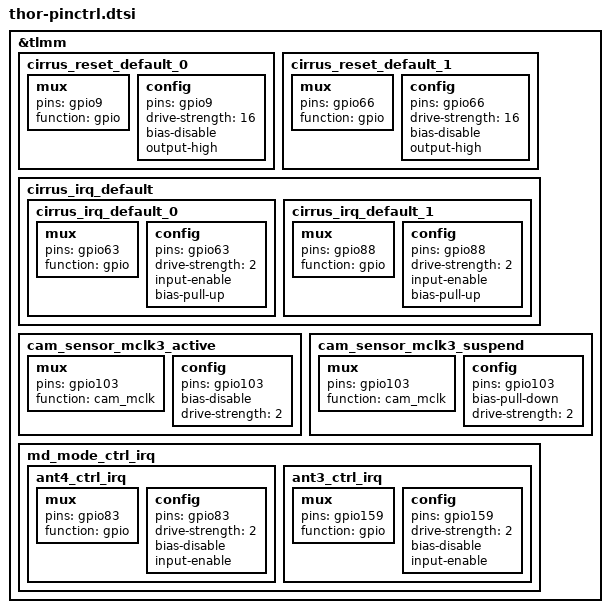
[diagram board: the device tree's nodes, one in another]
/*for thor pinctrl */

&tlmm {
	cirrus_reset_default_0: cirrus_reset_default_0 {
		mux {
			pins = "gpio9";
			function = "gpio";
		};

		config {
			pins = "gpio9";
			drive-strength = <16>;   /* 16 mA */
			bias-disable;
			output-high;
		};
	};

	cirrus_reset_default_1: cirrus_reset_default_1 {
		mux {
			pins = "gpio66";
			function = "gpio";
		};

		config {
			pins = "gpio66";
			drive-strength = <16>;   /* 16 mA */
			bias-disable;
			output-high;
		};
	};

	cirrus_irq_default {
		cirrus_irq_default_0: cirrus_irq_default_0 {
			mux {
					pins = "gpio63";
					function = "gpio";
			};
			config {
					pins = "gpio63";
					drive-strength = <2>;
					input-enable;
					bias-pull-up;
			};
		};
		cirrus_irq_default_1: cirrus_irq_default_1 {
			mux {
					pins = "gpio88";
					function = "gpio";
			};
			config {
					pins = "gpio88";
					drive-strength = <2>;
					input-enable;
					bias-pull-up;
			};
		};
	};

	cam_sensor_mclk3_active: cam_sensor_mclk3_active {
		/* MCLK3 */
		mux {
			pins = "gpio103";
			function = "cam_mclk";
		};

		config {
			pins = "gpio103";
			bias-disable; /* No PULL */
			drive-strength = <2>; /* 2 MA */
		};
	};

	cam_sensor_mclk3_suspend: cam_sensor_mclk3_suspend {
		/* MCLK3 */
		mux {
			pins = "gpio103";
			function = "cam_mclk";
		};

		config {
			pins = "gpio103";
			bias-pull-down; /* PULL DOWN */
			drive-strength = <2>; /* 2 MA */
		};
	};

	md_mode_ctrl_irq {
		ant4_ctrl_irq: ant4_ctrl_irq {
			mux {
				pins = "gpio83";
				function = "gpio";
			};

			config {
				pins = "gpio83";
				drive-strength = <2>;
				bias-disable;
				input-enable;
			};
		};

		ant3_ctrl_irq: ant3_ctrl_irq {
			mux {
				pins = "gpio159";
				function = "gpio";
			};

			config {
				pins = "gpio159";
				drive-strength = <2>;
				bias-disable;
				input-enable;
			};
		};
	};
};
